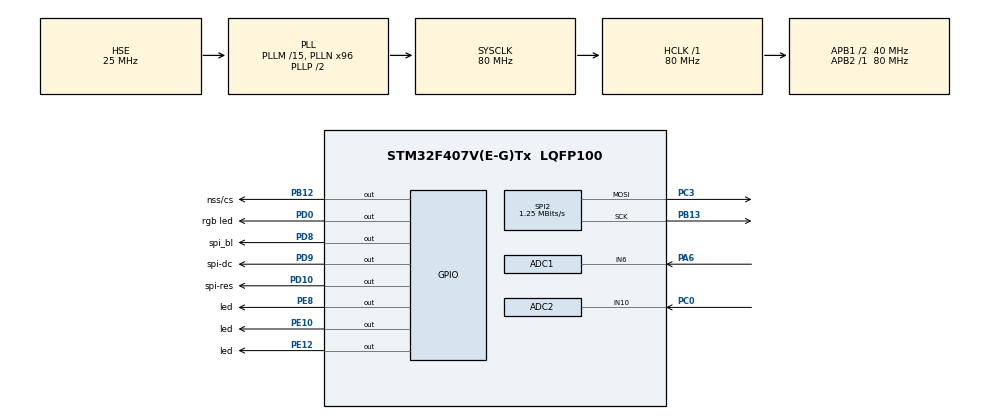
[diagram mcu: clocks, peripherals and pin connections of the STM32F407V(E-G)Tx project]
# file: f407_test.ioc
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ADC1.Channel-1\#ChannelRegularConversion=ADC_CHANNEL_6
ADC1.ClockPrescaler=ADC_CLOCK_SYNC_PCLK_DIV6
ADC1.NbrOfConversionFlag=1
ADC1.Rank-1\#ChannelRegularConversion=1
ADC1.SamplingTime-1\#ChannelRegularConversion=ADC_SAMPLETIME_3CYCLES
ADC1.master=1
ADC2.Channel-0\#ChannelRegularConversion=ADC_CHANNEL_10
ADC2.ClockPrescaler=ADC_CLOCK_SYNC_PCLK_DIV6
ADC2.NbrOfConversionFlag=1
ADC2.Rank-0\#ChannelRegularConversion=1
ADC2.SamplingTime-0\#ChannelRegularConversion=ADC_SAMPLETIME_3CYCLES
Mcu.Family=STM32F4
Mcu.Name=STM32F407V(E-G)Tx
Mcu.Package=LQFP100
NVIC.PriorityGroup=NVIC_PRIORITYGROUP_4
PA13.Mode=Serial_Wire
PA13.Signal=SYS_JTMS-SWDIO
PA14.Mode=Serial_Wire
PA14.Signal=SYS_JTCK-SWCLK
PA6.Signal=ADCx_IN6
PB12.GPIO_Label=nss/cs
PB12.GPIO_Speed=GPIO_SPEED_FREQ_HIGH
PB12.PinState=GPIO_PIN_SET
PB12.Signal=GPIO_Output
PB13.Mode=TX_Only_Simplex_Unidirect_Master
PB13.Signal=SPI2_SCK
PC0.Signal=ADCx_IN10
PC3.Mode=TX_Only_Simplex_Unidirect_Master
PC3.Signal=SPI2_MOSI
PD0.GPIO_Label=rgb led
PD0.Signal=GPIO_Output
PD10.GPIO_Label=spi-res
PD10.GPIO_ModeDefaultOutputPP=GPIO_MODE_OUTPUT_PP
PD10.GPIO_Speed=GPIO_SPEED_FREQ_HIGH
PD10.PinState=GPIO_PIN_SET
PD10.Signal=GPIO_Output
PD8.GPIO_Label=spi_bl
PD8.GPIO_ModeDefaultOutputPP=GPIO_MODE_OUTPUT_PP
PD8.GPIO_Speed=GPIO_SPEED_FREQ_HIGH
PD8.PinState=GPIO_PIN_SET
PD8.Signal=GPIO_Output
PD9.GPIO_Label=spi-dc
PD9.GPIO_ModeDefaultOutputPP=GPIO_MODE_OUTPUT_PP
PD9.GPIO_Speed=GPIO_SPEED_FREQ_HIGH
PD9.PinState=GPIO_PIN_SET
PD9.Signal=GPIO_Output
PE10.GPIO_Label=led
PE10.PinState=GPIO_PIN_RESET
PE10.Signal=GPIO_Output
PE12.GPIO_Label=led
PE12.PinState=GPIO_PIN_RESET
PE12.Signal=GPIO_Output
PE8.GPIO_Label=led
PE8.PinState=GPIO_PIN_RESET
PE8.Signal=GPIO_Output
PH0-OSC_IN.Mode=HSE-External-Oscillator
PH0-OSC_IN.Signal=RCC_OSC_IN
PH1-OSC_OUT.Mode=HSE-External-Oscillator
PH1-OSC_OUT.Signal=RCC_OSC_OUT
ProjectManager.HeapSize=0x200
ProjectManager.StackSize=0x400
ProjectManager.TargetToolchain=CMake
RCC.48MHZClocksFreq_Value=40000000
RCC.AHBFreq_Value=80000000
RCC.APB1CLKDivider=RCC_HCLK_DIV2
RCC.APB1Freq_Value=40000000
RCC.APB1TimFreq_Value=80000000
RCC.APB2Freq_Value=80000000
RCC.APB2TimFreq_Value=80000000
RCC.CortexFreq_Value=80000000
RCC.HCLKFreq_Value=80000000
RCC.HSE_VALUE=25000000
RCC.HSI_VALUE=16000000
RCC.LSE_VALUE=32768
RCC.PLLM=15
RCC.PLLN=96
RCC.PLLSourceVirtual=RCC_PLLSOURCE_HSE
RCC.SYSCLKFreq_VALUE=80000000
RCC.SYSCLKSource=RCC_SYSCLKSOURCE_PLLCLK
RCC.VCOOutputFreq_Value=160000000
SH.ADCx_IN10.0=ADC2_IN10,IN10
SH.ADCx_IN6.0=ADC1_IN6,IN6
SPI2.BaudRatePrescaler=SPI_BAUDRATEPRESCALER_32
SPI2.CalculateBaudRate=1.25 MBits/s
SPI2.Direction=SPI_DIRECTION_2LINES
SPI2.Mode=SPI_MODE_MASTER
SPI2.VirtualType=VM_MASTER
board=custom

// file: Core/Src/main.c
/* USER CODE BEGIN Header */
/**
  ******************************************************************************
  * @file           : main.c
  * @brief          : Main program body
  ******************************************************************************
  * @attention
  *
  * Copyright (c) 2026 STMicroelectronics.
  * All rights reserved.
  *
  * This software is licensed under terms that can be found in the LICENSE file
  * in the root directory of this software component.
  * If no LICENSE file comes with this software, it is provided AS-IS.
  *
  ******************************************************************************
  */
/* USER CODE END Header */
#include "main.h"
#include "adc.h"
#include "spi.h"
#include "gpio.h"

/* USER CODE BEGIN Includes */
#include "tft.h"
/* USER CODE END Includes */

void SystemClock_Config(void);

int main(void)
{

  /* MCU Configuration--------------------------------------------------------*/

  /* Reset of all peripherals, Initializes the Flash interface and the Systick. */
  HAL_Init();

  /* Configure the system clock */
  SystemClock_Config();

  /* Initialize all configured peripherals */
  MX_GPIO_Init();
  MX_ADC1_Init();
  MX_ADC2_Init();
  MX_SPI2_Init();

  /* Infinite loop */
  /* USER CODE BEGIN WHILE */
  // 1. 初始化屏幕硬件与内部寄存器
  TFT_Init();

  // 2. 测试指令：将屏幕刷成纯红色
  TFT_Fill(TFT_BLACK);

TFT_ShowString(10, 20, "STM32 TFT OK!", TFT_WHITE, TFT_BLACK);

  // 3. 测试数字和符号
  TFT_ShowString(10, 50, "Test: 12345", TFT_YELLOW, TFT_BLACK);
TFT_ShowChineseStr(10, 70, "孙伟大王", TFT_GREEN, TFT_BLACK);

  while (1)
  {
    HAL_GPIO_WritePin(GPIOE, GPIO_PIN_8, GPIO_PIN_SET);
     HAL_GPIO_WritePin(GPIOE, GPIO_PIN_10, GPIO_PIN_SET);
      HAL_GPIO_WritePin(GPIOE, GPIO_PIN_12, GPIO_PIN_SET);
       HAL_GPIO_WritePin(GPIOD, GPIO_PIN_0, GPIO_PIN_SET);

    /* USER CODE END WHILE */

    /* USER CODE BEGIN 3 */
  }
  return 0;
  /* USER CODE END 3 */
}

void SystemClock_Config(void)
{
  RCC_OscInitTypeDef RCC_OscInitStruct = {0};
  RCC_ClkInitTypeDef RCC_ClkInitStruct = {0};

  /** Configure the main internal regulator output voltage
  */
  __HAL_RCC_PWR_CLK_ENABLE();
  __HAL_PWR_VOLTAGESCALING_CONFIG(PWR_REGULATOR_VOLTAGE_SCALE1);

  /** Initializes the RCC Oscillators according to the specified parameters
  * in the RCC_OscInitTypeDef structure.
  */
  RCC_OscInitStruct.OscillatorType = RCC_OSCILLATORTYPE_HSE;
  RCC_OscInitStruct.HSEState = RCC_HSE_ON;
  RCC_OscInitStruct.PLL.PLLState = RCC_PLL_ON;
  RCC_OscInitStruct.PLL.PLLSource = RCC_PLLSOURCE_HSE;
  RCC_OscInitStruct.PLL.PLLM = 15;
  RCC_OscInitStruct.PLL.PLLN = 96;
  RCC_OscInitStruct.PLL.PLLP = RCC_PLLP_DIV2;
  RCC_OscInitStruct.PLL.PLLQ = 4;
  if (HAL_RCC_OscConfig(&RCC_OscInitStruct) != HAL_OK)
  {
    Error_Handler();
  }

  /** Initializes the CPU, AHB and APB buses clocks
  */
  RCC_ClkInitStruct.ClockType = RCC_CLOCKTYPE_HCLK|RCC_CLOCKTYPE_SYSCLK
                              |RCC_CLOCKTYPE_PCLK1|RCC_CLOCKTYPE_PCLK2;
  RCC_ClkInitStruct.SYSCLKSource = RCC_SYSCLKSOURCE_PLLCLK;
  RCC_ClkInitStruct.AHBCLKDivider = RCC_SYSCLK_DIV1;
  RCC_ClkInitStruct.APB1CLKDivider = RCC_HCLK_DIV2;
  RCC_ClkInitStruct.APB2CLKDivider = RCC_HCLK_DIV1;

  if (HAL_RCC_ClockConfig(&RCC_ClkInitStruct, FLASH_LATENCY_2) != HAL_OK)
  {
    Error_Handler();
  }
}

void Error_Handler(void)
{
  __disable_irq();
  while (1)
  {
  }
}
